# DSS_REG2 register map
Vendor: Texas Instruments
Peripheral module from a debugger description file (folder radar).
Registers are 32-bit, read-write, no defined reset value unless marked. A register's access mark holds for its fields unless they carry their own. Offsets are as the file gives them; lines under a group give offsets from that group; [hi:lo] are bit positions; {n}, {i} and the like mark numbered series; 'fields as' and 'values as' point back to an identical list; <NAME> marks a mode.

## DSS_REG2
{0x100+4i} TPTC2WRMPUSTADD{i} (i=0..5)
  [31:0] TPTC2WRMPUSTADD{i} — Configure the Start address for Region {i} for the MPU on the write port of TPTC2
{0x120+4i} TPTC2WRMPUENDADD{i} (i=0..5)
  [31:0] TPTC2WRMPUENDADD{i} — Configure the End address for Region {i} for the MPU on the write port of TPTC2
0x140 TPTC2WRMPUERRADD ro
  [31:0] TPTC2WRMPUERRADD — Status register to Read the address that triggered an MPU error on the write port of TPTC2
{0x148+4i} TPTC2RDMPUSTADD{i} (i=0..5)
  [31:0] TPTC2RDMPUSTADD{i} — Configure the Start address for Region {i} for the MPU on the read port of TPTC2
{0x168+4i} TPTC2RDMPUENDADD{i} (i=0..5)
  [31:0] TPTC2RDMPUENDADD{i} — Configure the End address for Region {i} for the MPU on the read port of TPTC2
0x188 TPTC2RDMPUERRADD ro
  [31:0] TPTC2RDMPUERRADD — Status register to Read the address that triggered an MPU error on the read port of TPTC2
{0x18C+4i} TPTC3WRMPUSTADD{i} (i=0..5)
  [31:0] TPTC3WRMPUSTADD{i} — Configure the Start address for Region {i} for the MPU on the write port of TPTC3
{0x1AC+4i} TPTC3WRMPUENDADD{i} (i=0..5)
  [31:0] TPTC3WRMPUENDADD{i} — Configure the End address for Region {i} for the MPU on the write port of TPTC3
0x1CC TPTC3WRMPUERRADD ro
  [31:0] TPTC3WRMPUERRADD — Status register to Read the address that triggered an MPU error on the write port of TPTC3
{0x1D0+4i} TPTC3RDMPUSTADD{i} (i=0..5)
  [31:0] TPTC3RDMPUSTADD{i} — Configure the Start address for Region {i} for the MPU on the read port of TPTC3
{0x1F0+4i} TPTC3RDMPUENDADD{i} (i=0..5)
  [31:0] TPTC3RDMPUENDADD{i} — Configure the End address for Region {i} for the MPU on the read port of TPTC3
0x210 TPTC3RDMPUERRADD ro
  [31:0] TPTC3RDMPUERRADD — Status register to Read the address that triggered an MPU error on the read port of TPTC3
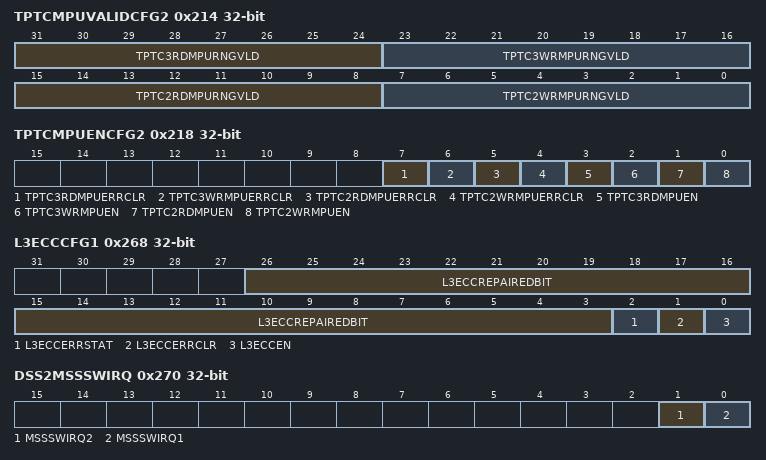
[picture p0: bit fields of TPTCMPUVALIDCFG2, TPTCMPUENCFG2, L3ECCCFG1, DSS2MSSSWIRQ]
0x214 TPTCMPUVALIDCFG2
  [31:24] TPTC3RDMPURNGVLD — Configure the Valid bit for each address range for the MPU in the read port of TPTC3. [0]->Address0 and [5]-->Address5 Each bit corresponds to a MPU region 0 : Region is disbaled 1 : Regsion is enabled
  [23:16] TPTC3WRMPURNGVLD — Configure the Valid bit for each address range for the MPU in the write port of TPTC3. [0]->Address0 and [5]-->Address5 Each bit corresponds to a MPU region 0 : Region is disbaled 1 : Regsion is enabled
  [15:8] TPTC2RDMPURNGVLD — Configure the Valid bit for each address range for the MPU in the read port of TPTC2. [0]->Address0 and [5]-->Address5 Each bit corresponds to a MPU region 0 : Region is disbaled 1 : Regsion is enabled
  [7:0] TPTC2WRMPURNGVLD — Configure the Valid bit for each address range for the MPU in the write port of TPTC2. [0]->Address0 and [5]-->Address5 Each bit corresponds to a MPU region 0 : Region is disbaled 1 : Regsion is enabled
0x218 TPTCMPUENCFG2 access not given
  [7] TPTC3RDMPUERRCLR — Clear flag for Error from the MPU in the read port of TPTC3. Write 0x1 to clear the MPU error
  [6] TPTC3WRMPUERRCLR — Clear flag for Error from the MPU in the write port of TPTC3. Write 0x1 to clear the MPU error
  [5] TPTC2RDMPUERRCLR — Clear flag for Error from the MPU in the read port of TPTC2. Write 0x1 to clear the MPU error
  [4] TPTC2WRMPUERRCLR — Clear flag for Error from the MPU in the write port of TPTC2. Write 0x1 to clear the MPU error
  [3] TPTC3RDMPUEN rw — Enable bit for the MPU in the read port of TPTC3. 0 : MPU is disabled 1 : MPU is enabled
  [2] TPTC3WRMPUEN rw — Enable bit for the MPU in the write port of TPTC3. 0 : MPU is disabled 1 : MPU is enabled
  [1] TPTC2RDMPUEN rw — Enable bit for the MPU in the read port of TPTC2. 0 : MPU is disabled 1 : MPU is enabled
  [0] TPTC2WRMPUEN rw — Enable bit for the MPU in the write port of TPTC2. 0 : MPU is disabled 1 : MPU is enabled
0x268 L3ECCCFG1 access not given
  [26:3] L3ECCREPAIREDBIT ro — Bit position of repaired bit in L3 ECC memory. Each 6 bits out is this register maps to the corresponding 32 bit location in the data.
  [2] L3ECCERRSTAT ro — Latched status for L3 ECC error.
  [1] L3ECCERRCLR — Clear bit for L3 ECC.
  [0] L3ECCEN rw — Enable for L3 ECC logic
0x26C L3ECCCFG2 ro
  [16:0] L3ECCFAULTADDR — Fault address of L3 ECC memory.
0x270 DSS2MSSSWIRQ access not given
  [1] MSSSWIRQ2 — single bit and self clearing interrupt. writing a '1' to this bit will generate a pulse from DSS to MSS VIM line 61
  [0] MSSSWIRQ1 — single bit and self clearing interrupt. writing a '1' to this bit will generate a pulse from DSS to MSS VIM line 52
